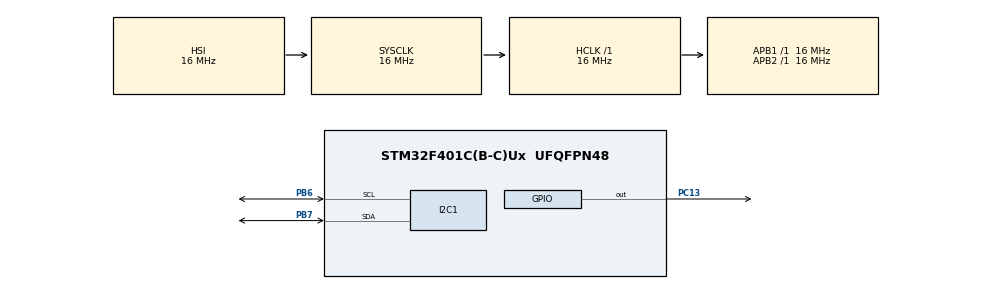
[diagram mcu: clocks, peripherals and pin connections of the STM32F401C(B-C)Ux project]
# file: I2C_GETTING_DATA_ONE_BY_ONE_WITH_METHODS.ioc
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I2C1.OwnAddress=0
Mcu.Family=STM32F4
Mcu.Name=STM32F401C(B-C)Ux
Mcu.Package=UFQFPN48
NVIC.PriorityGroup=NVIC_PRIORITYGROUP_4
PB6.Mode=I2C
PB6.Signal=I2C1_SCL
PB7.Mode=I2C
PB7.Signal=I2C1_SDA
PC13-ANTI_TAMP.Signal=GPIO_Output
ProjectManager.HeapSize=0x200
ProjectManager.StackSize=0x400
ProjectManager.TargetToolchain=STM32CubeIDE
RCC.AHBFreq_Value=16000000
RCC.APB1Freq_Value=16000000
RCC.APB2Freq_Value=16000000
RCC.CortexFreq_Value=16000000
RCC.HSE_VALUE=25000000
RCC.HSI_VALUE=16000000
RCC.LSE_VALUE=32768
RCC.SYSCLKFreq_VALUE=16000000
RCC.VCOOutputFreq_Value=192000000
board=custom

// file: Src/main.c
/* USER CODE BEGIN Header */
/**
  ******************************************************************************
  * @file           : main.c
  * @brief          : Main program body
  ******************************************************************************
  * @attention
  *
  * Copyright (c) 2024 STMicroelectronics.
  * All rights reserved.
  *
  * This software is licensed under terms that can be found in the LICENSE file
  * in the root directory of this software component.
  * If no LICENSE file comes with this software, it is provided AS-IS.
  *
  ******************************************************************************
  */
/* USER CODE END Header */
#include "main.h"

I2C_HandleTypeDef hi2c1;

/* USER CODE BEGIN PV */
uint8_t buff[5];
uint8_t a, b, c, d, e;
/* USER CODE END PV */

void SystemClock_Config(void);
static void MX_GPIO_Init(void);
static void MX_I2C1_Init(void);
/* USER CODE BEGIN PFP */
void method1(uint8_t data);
void method2(uint8_t data);
void method3(uint8_t data);
void method4(uint8_t data);
void method5(uint8_t data);
void value_assign(void);
/* USER CODE END PFP */

int main(void)
{

  /* MCU Configuration--------------------------------------------------------*/

  /* Reset of all peripherals, Initializes the Flash interface and the Systick. */
  HAL_Init();

  /* Configure the system clock */
  SystemClock_Config();

  /* Initialize all configured peripherals */
  MX_GPIO_Init();
  MX_I2C1_Init();

  /* Infinite loop */
  while (1)
  {
	  /**
	       * @brief Receives data from I2C device and assigns values to global variables.
	       *
	       * This function uses the HAL library to receive data from an I2C device with
	       * address 0x05. If the receive operation is successful, the received data is
	       * stored in the buffer 'buff', and then the function 'value_assign' is called
	       * to assign these values to global variables and perform additional processing.
	       * If the receive operation fails, the function 'Error_Handler' is called.
	       */
	  if (HAL_I2C_Master_Receive(&hi2c1, 0x05 << 1, buff, sizeof(buff), HAL_MAX_DELAY) != HAL_OK)
	  {
	        Error_Handler();
	      } else {

	    	  value_assign();
	      }

	      HAL_Delay(1000);
  }
}

/**
  * @brief Assigns values to global variables a, b, c, d, e from buffer.
  *
  * This function retrieves values from a global buffer and assigns them
  * to global variables a, b, c, d, and e respectively. After assigning
  * each value, corresponding methods (method1 to method5) are called
  * to perform additional processing on each variable.
  */
void value_assign(void)
{
	a=buff[0];
	b=buff[1];
	c=buff[2];
	d=buff[3];
	e=buff[4];

    method1(a);
    method2(b);
    method3(c);
    method4(d);
    method5(e);
}

/**
  * @brief Modifies the value of global variable a.
  *
  * This function takes a parameter 'data', increments it by 1, and then
  * assigns the result to the global variable 'a'.
  *
  * @param data Input value to be incremented.
  */
void method1(uint8_t data)
{
  a=data+1;
}

/**
  * @brief Modifies the value of global variable b.
  *
  * This function takes a parameter 'data', increments it by 1, and then
  * assigns the result to the global variable 'b'.
  *
  * @param data Input value to be incremented.
  */
void method2(uint8_t data)
{
  b=data+1;
}

/**
  * @brief Modifies the value of global variable c.
  *
  * This function takes a parameter 'data', increments it by 1, and then
  * assigns the result to the global variable 'c'.
  *
  * @param data Input value to be incremented.
  */
void method3(uint8_t data)
{
  c=data+1;
}

/**
  * @brief Modifies the value of global variable d.
  *
  * This function takes a parameter 'data', increments it by 1, and then
  * assigns the result to the global variable 'd'.
  *
  * @param data Input value to be incremented.
  */
void method4(uint8_t data)
{
  d=data+1;
}

/**
  * @brief Modifies the value of global variable e.
  *
  * This function takes a parameter 'data', increments it by 1, and then
  * assigns the result to the global variable 'e'.
  *
  * @param data Input value to be incremented.
  */
void method5(uint8_t data)
{
  e=data+1;
}

void SystemClock_Config(void)
{
  RCC_OscInitTypeDef RCC_OscInitStruct = {0};
  RCC_ClkInitTypeDef RCC_ClkInitStruct = {0};

  /** Configure the main internal regulator output voltage
  */
  __HAL_RCC_PWR_CLK_ENABLE();
  __HAL_PWR_VOLTAGESCALING_CONFIG(PWR_REGULATOR_VOLTAGE_SCALE2);

  /** Initializes the RCC Oscillators according to the specified parameters
  * in the RCC_OscInitTypeDef structure.
  */
  RCC_OscInitStruct.OscillatorType = RCC_OSCILLATORTYPE_HSI;
  RCC_OscInitStruct.HSIState = RCC_HSI_ON;
  RCC_OscInitStruct.HSICalibrationValue = RCC_HSICALIBRATION_DEFAULT;
  RCC_OscInitStruct.PLL.PLLState = RCC_PLL_NONE;
  if (HAL_RCC_OscConfig(&RCC_OscInitStruct) != HAL_OK)
  {
    Error_Handler();
  }

  /** Initializes the CPU, AHB and APB buses clocks
  */
  RCC_ClkInitStruct.ClockType = RCC_CLOCKTYPE_HCLK|RCC_CLOCKTYPE_SYSCLK
                              |RCC_CLOCKTYPE_PCLK1|RCC_CLOCKTYPE_PCLK2;
  RCC_ClkInitStruct.SYSCLKSource = RCC_SYSCLKSOURCE_HSI;
  RCC_ClkInitStruct.AHBCLKDivider = RCC_SYSCLK_DIV1;
  RCC_ClkInitStruct.APB1CLKDivider = RCC_HCLK_DIV1;
  RCC_ClkInitStruct.APB2CLKDivider = RCC_HCLK_DIV1;

  if (HAL_RCC_ClockConfig(&RCC_ClkInitStruct, FLASH_LATENCY_0) != HAL_OK)
  {
    Error_Handler();
  }
}

static void MX_I2C1_Init(void)
{

  hi2c1.Instance = I2C1;
  hi2c1.Init.ClockSpeed = 100000;
  hi2c1.Init.DutyCycle = I2C_DUTYCYCLE_2;
  hi2c1.Init.OwnAddress1 = 0;
  hi2c1.Init.AddressingMode = I2C_ADDRESSINGMODE_7BIT;
  hi2c1.Init.DualAddressMode = I2C_DUALADDRESS_DISABLE;
  hi2c1.Init.OwnAddress2 = 0;
  hi2c1.Init.GeneralCallMode = I2C_GENERALCALL_DISABLE;
  hi2c1.Init.NoStretchMode = I2C_NOSTRETCH_ENABLE;
  if (HAL_I2C_Init(&hi2c1) != HAL_OK)
  {
    Error_Handler();
  }
}

static void MX_GPIO_Init(void)
{
  GPIO_InitTypeDef GPIO_InitStruct = {0};

  /* GPIO Ports Clock Enable */
  __HAL_RCC_GPIOC_CLK_ENABLE();
  __HAL_RCC_GPIOB_CLK_ENABLE();

  /*Configure GPIO pin Output Level */
  HAL_GPIO_WritePin(GPIOC, GPIO_PIN_13, GPIO_PIN_RESET);

  /*Configure GPIO pin : PC13 */
  GPIO_InitStruct.Pin = GPIO_PIN_13;
  GPIO_InitStruct.Mode = GPIO_MODE_OUTPUT_PP;
  GPIO_InitStruct.Pull = GPIO_NOPULL;
  GPIO_InitStruct.Speed = GPIO_SPEED_FREQ_LOW;
  HAL_GPIO_Init(GPIOC, &GPIO_InitStruct);
}

void Error_Handler(void)
{
  __disable_irq();
  while (1)
  {
  }
}
